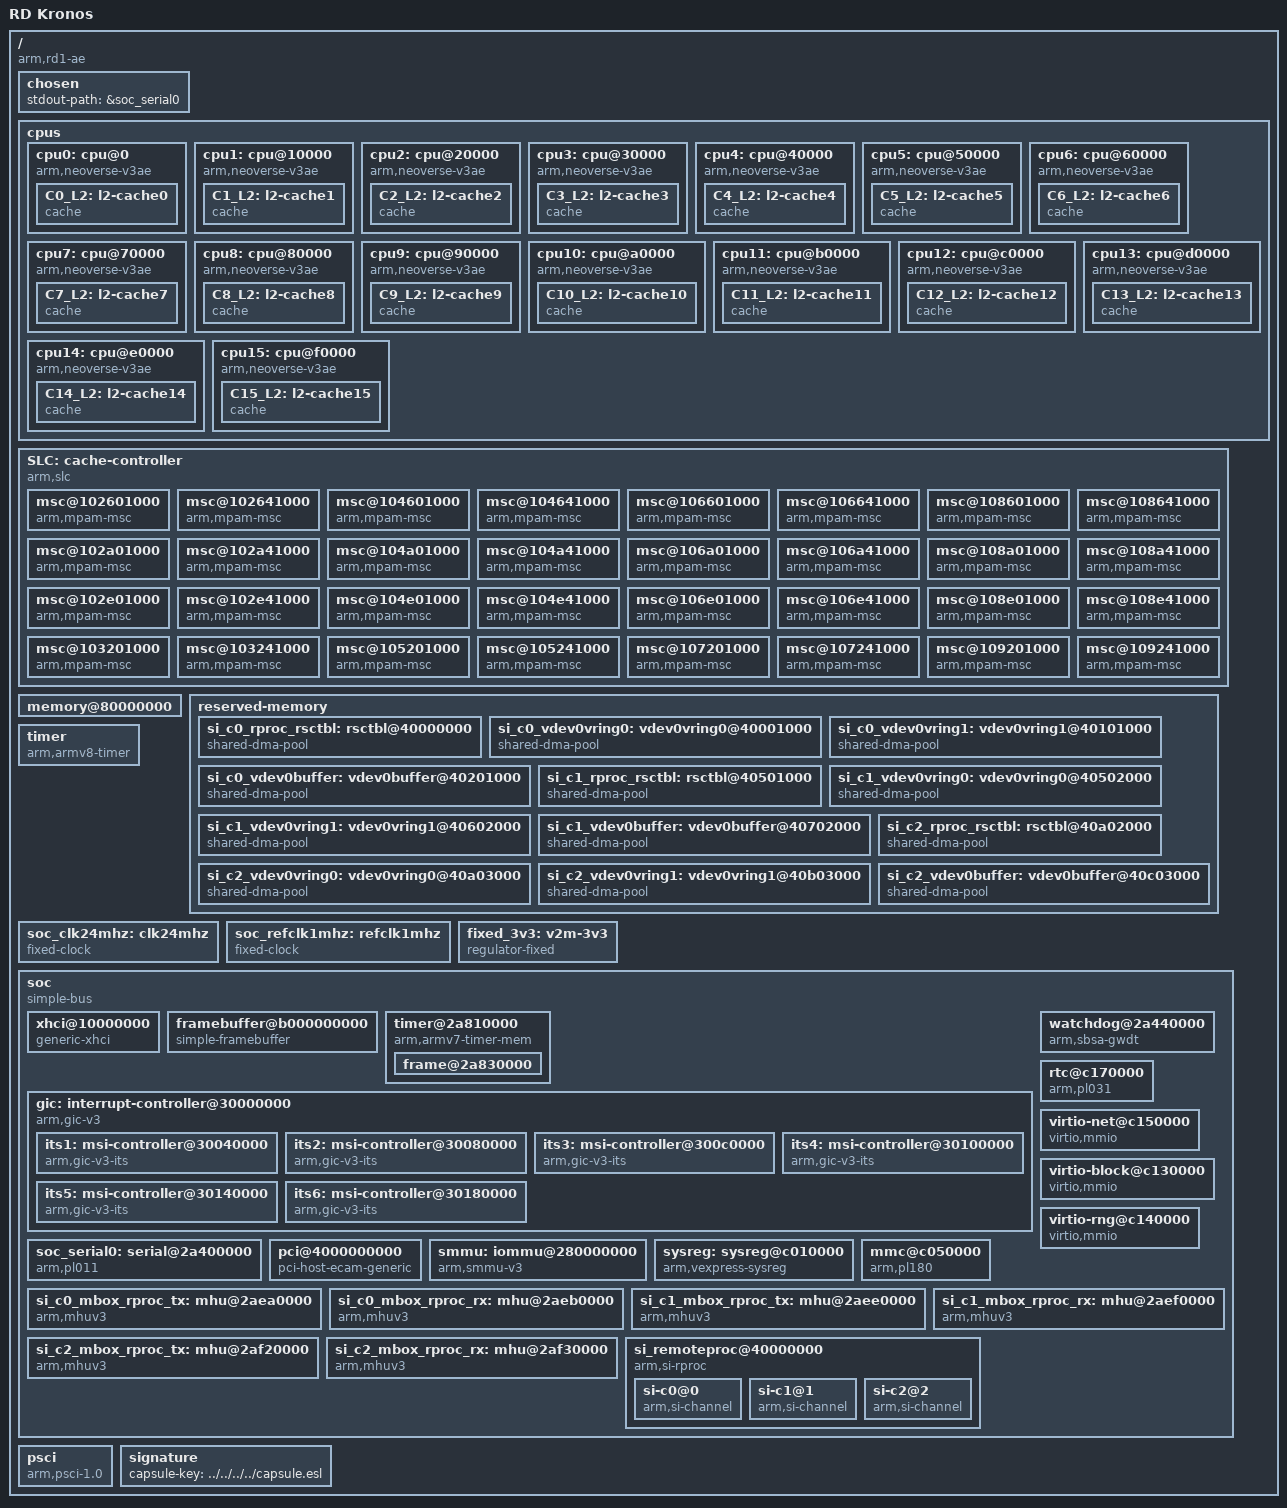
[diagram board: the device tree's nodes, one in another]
/*
 * SPDX-FileCopyrightText: <text>Copyright 2024 Arm Limited and/or its
 * affiliates <open-source-office@arm.com></text>
 *
 * SPDX-License-Identifier: MIT
 */

/dts-v1/;

#include <dt-bindings/interrupt-controller/arm-gic.h>

/ {
	model = "RD Kronos";
	compatible = "arm,rd1-ae";
	interrupt-parent = <&gic>;
	#address-cells = <2>;
	#size-cells = <2>;

	chosen {
		stdout-path = &soc_serial0;
	};

	cpus {
		#address-cells = <2>;
		#size-cells = <0>;

		cpu0: cpu@0 {
			device_type = "cpu";
			compatible = "arm,neoverse-v3ae";
			reg = <0x0 0x0>;
			enable-method = "psci";
			i-cache-size = <0x10000>;
			i-cache-line-size = <0x40>;
			i-cache-sets = <0x100>;
			d-cache-size = <0x10000>;
			d-cache-line-size = <0x40>;
			d-cache-sets = <0x100>;
			next-level-cache = <&C0_L2>;

			C0_L2: l2-cache0 {
				compatible = "cache";
				cache-unified;
				cache-level = <0x02>;
				cache-size = <0x100000>;
				cache-line-size = <0x40>;
				cache-sets = <0x800>;
				next-level-cache = <&SLC>;
			};
		};
		cpu1: cpu@10000 {
			device_type = "cpu";
			compatible = "arm,neoverse-v3ae";
			reg = <0x0 0x10000>;
			enable-method = "psci";
			i-cache-size = <0x10000>;
			i-cache-line-size = <0x40>;
			i-cache-sets = <0x100>;
			d-cache-size = <0x10000>;
			d-cache-line-size = <0x40>;
			d-cache-sets = <0x100>;
			next-level-cache = <&C1_L2>;

			C1_L2: l2-cache1 {
				compatible = "cache";
				cache-unified;
				cache-level = <0x02>;
				cache-size = <0x100000>;
				cache-line-size = <0x40>;
				cache-sets = <0x800>;
				next-level-cache = <&SLC>;
			};
		};
		cpu2: cpu@20000 {
			device_type = "cpu";
			compatible = "arm,neoverse-v3ae";
			reg = <0x0 0x20000>;
			enable-method = "psci";
			i-cache-size = <0x10000>;
			i-cache-line-size = <0x40>;
			i-cache-sets = <0x100>;
			d-cache-size = <0x10000>;
			d-cache-line-size = <0x40>;
			d-cache-sets = <0x100>;
			next-level-cache = <&C2_L2>;

			C2_L2: l2-cache2 {
				compatible = "cache";
				cache-unified;
				cache-level = <0x02>;
				cache-size = <0x100000>;
				cache-line-size = <0x40>;
				cache-sets = <0x800>;
				next-level-cache = <&SLC>;
			};
		};
		cpu3: cpu@30000 {
			device_type = "cpu";
			compatible = "arm,neoverse-v3ae";
			reg = <0x0 0x30000>;
			enable-method = "psci";
			i-cache-size = <0x10000>;
			i-cache-line-size = <0x40>;
			i-cache-sets = <0x100>;
			d-cache-size = <0x10000>;
			d-cache-line-size = <0x40>;
			d-cache-sets = <0x100>;
			next-level-cache = <&C3_L2>;

			C3_L2: l2-cache3 {
				compatible = "cache";
				cache-unified;
				cache-level = <0x02>;
				cache-size = <0x100000>;
				cache-line-size = <0x40>;
				cache-sets = <0x800>;
				next-level-cache = <&SLC>;
			};
		};
		cpu4: cpu@40000 {
			device_type = "cpu";
			compatible = "arm,neoverse-v3ae";
			reg = <0x0 0x40000>;
			enable-method = "psci";
			i-cache-size = <0x10000>;
			i-cache-line-size = <0x40>;
			i-cache-sets = <0x100>;
			d-cache-size = <0x10000>;
			d-cache-line-size = <0x40>;
			d-cache-sets = <0x100>;
			next-level-cache = <&C4_L2>;

			C4_L2: l2-cache4 {
				compatible = "cache";
				cache-unified;
				cache-level = <0x02>;
				cache-size = <0x100000>;
				cache-line-size = <0x40>;
				cache-sets = <0x800>;
				next-level-cache = <&SLC>;
			};
		};
		cpu5: cpu@50000 {
			device_type = "cpu";
			compatible = "arm,neoverse-v3ae";
			reg = <0x0 0x50000>;
			enable-method = "psci";
			i-cache-size = <0x10000>;
			i-cache-line-size = <0x40>;
			i-cache-sets = <0x100>;
			d-cache-size = <0x10000>;
			d-cache-line-size = <0x40>;
			d-cache-sets = <0x100>;
			next-level-cache = <&C5_L2>;

			C5_L2: l2-cache5 {
				compatible = "cache";
				cache-unified;
				cache-level = <0x02>;
				cache-size = <0x100000>;
				cache-line-size = <0x40>;
				cache-sets = <0x800>;
				next-level-cache = <&SLC>;
			};
		};
		cpu6: cpu@60000 {
			device_type = "cpu";
			compatible = "arm,neoverse-v3ae";
			reg = <0x0 0x60000>;
			enable-method = "psci";
			i-cache-size = <0x10000>;
			i-cache-line-size = <0x40>;
			i-cache-sets = <0x100>;
			d-cache-size = <0x10000>;
			d-cache-line-size = <0x40>;
			d-cache-sets = <0x100>;
			next-level-cache = <&C6_L2>;

			C6_L2: l2-cache6 {
				compatible = "cache";
				cache-unified;
				cache-level = <0x02>;
				cache-size = <0x100000>;
				cache-line-size = <0x40>;
				cache-sets = <0x800>;
				next-level-cache = <&SLC>;
			};
		};
		cpu7: cpu@70000 {
			device_type = "cpu";
			compatible = "arm,neoverse-v3ae";
			reg = <0x0 0x70000>;
			enable-method = "psci";
			i-cache-size = <0x10000>;
			i-cache-line-size = <0x40>;
			i-cache-sets = <0x100>;
			d-cache-size = <0x10000>;
			d-cache-line-size = <0x40>;
			d-cache-sets = <0x100>;
			next-level-cache = <&C7_L2>;

			C7_L2: l2-cache7 {
				compatible = "cache";
				cache-unified;
				cache-level = <0x02>;
				cache-size = <0x100000>;
				cache-line-size = <0x40>;
				cache-sets = <0x800>;
				next-level-cache = <&SLC>;
			};
		};
		cpu8: cpu@80000 {
			device_type = "cpu";
			compatible = "arm,neoverse-v3ae";
			reg = <0x0 0x80000>;
			enable-method = "psci";
			i-cache-size = <0x10000>;
			i-cache-line-size = <0x40>;
			i-cache-sets = <0x100>;
			d-cache-size = <0x10000>;
			d-cache-line-size = <0x40>;
			d-cache-sets = <0x100>;
			next-level-cache = <&C8_L2>;

			C8_L2: l2-cache8 {
				compatible = "cache";
				cache-unified;
				cache-level = <0x02>;
				cache-size = <0x100000>;
				cache-line-size = <0x40>;
				cache-sets = <0x800>;
				next-level-cache = <&SLC>;
			};
		};
		cpu9: cpu@90000 {
			device_type = "cpu";
			compatible = "arm,neoverse-v3ae";
			reg = <0x0 0x90000>;
			enable-method = "psci";
			i-cache-size = <0x10000>;
			i-cache-line-size = <0x40>;
			i-cache-sets = <0x100>;
			d-cache-size = <0x10000>;
			d-cache-line-size = <0x40>;
			d-cache-sets = <0x100>;
			next-level-cache = <&C9_L2>;

			C9_L2: l2-cache9 {
				compatible = "cache";
				cache-unified;
				cache-level = <0x02>;
				cache-size = <0x100000>;
				cache-line-size = <0x40>;
				cache-sets = <0x800>;
				next-level-cache = <&SLC>;
			};
		};
		cpu10: cpu@a0000 {
			device_type = "cpu";
			compatible = "arm,neoverse-v3ae";
			reg = <0x0 0xa0000>;
			enable-method = "psci";
			i-cache-size = <0x10000>;
			i-cache-line-size = <0x40>;
			i-cache-sets = <0x100>;
			d-cache-size = <0x10000>;
			d-cache-line-size = <0x40>;
			d-cache-sets = <0x100>;
			next-level-cache = <&C10_L2>;

			C10_L2: l2-cache10 {
				compatible = "cache";
				cache-unified;
				cache-level = <0x02>;
				cache-size = <0x100000>;
				cache-line-size = <0x40>;
				cache-sets = <0x800>;
				next-level-cache = <&SLC>;
			};
		};
		cpu11: cpu@b0000 {
			device_type = "cpu";
			compatible = "arm,neoverse-v3ae";
			reg = <0x0 0xb0000>;
			enable-method = "psci";
			i-cache-size = <0x10000>;
			i-cache-line-size = <0x40>;
			i-cache-sets = <0x100>;
			d-cache-size = <0x10000>;
			d-cache-line-size = <0x40>;
			d-cache-sets = <0x100>;
			next-level-cache = <&C11_L2>;

			C11_L2: l2-cache11 {
				compatible = "cache";
				cache-unified;
				cache-level = <0x02>;
				cache-size = <0x100000>;
				cache-line-size = <0x40>;
				cache-sets = <0x800>;
				next-level-cache = <&SLC>;
			};
		};
		cpu12: cpu@c0000 {
			device_type = "cpu";
			compatible = "arm,neoverse-v3ae";
			reg = <0x0 0xc0000>;
			enable-method = "psci";
			i-cache-size = <0x10000>;
			i-cache-line-size = <0x40>;
			i-cache-sets = <0x100>;
			d-cache-size = <0x10000>;
			d-cache-line-size = <0x40>;
			d-cache-sets = <0x100>;
			next-level-cache = <&C12_L2>;

			C12_L2: l2-cache12 {
				compatible = "cache";
				cache-unified;
				cache-level = <0x02>;
				cache-size = <0x100000>;
				cache-line-size = <0x40>;
				cache-sets = <0x800>;
				next-level-cache = <&SLC>;
			};
		};
		cpu13: cpu@d0000 {
			device_type = "cpu";
			compatible = "arm,neoverse-v3ae";
			reg = <0x0 0xd0000>;
			enable-method = "psci";
			i-cache-size = <0x10000>;
			i-cache-line-size = <0x40>;
			i-cache-sets = <0x100>;
			d-cache-size = <0x10000>;
			d-cache-line-size = <0x40>;
			d-cache-sets = <0x100>;
			next-level-cache = <&C13_L2>;

			C13_L2: l2-cache13 {
				compatible = "cache";
				cache-unified;
				cache-level = <0x02>;
				cache-size = <0x100000>;
				cache-line-size = <0x40>;
				cache-sets = <0x800>;
				next-level-cache = <&SLC>;
			};
		};
		cpu14: cpu@e0000 {
			device_type = "cpu";
			compatible = "arm,neoverse-v3ae";
			reg = <0x0 0xe0000>;
			enable-method = "psci";
			i-cache-size = <0x10000>;
			i-cache-line-size = <0x40>;
			i-cache-sets = <0x100>;
			d-cache-size = <0x10000>;
			d-cache-line-size = <0x40>;
			d-cache-sets = <0x100>;
			next-level-cache = <&C14_L2>;

			C14_L2: l2-cache14 {
				compatible = "cache";
				cache-unified;
				cache-level = <0x02>;
				cache-size = <0x100000>;
				cache-line-size = <0x40>;
				cache-sets = <0x800>;
				next-level-cache = <&SLC>;
			};
		};
		cpu15: cpu@f0000 {
			device_type = "cpu";
			compatible = "arm,neoverse-v3ae";
			reg = <0x0 0xf0000>;
			enable-method = "psci";
			i-cache-size = <0x10000>;
			i-cache-line-size = <0x40>;
			i-cache-sets = <0x100>;
			d-cache-size = <0x10000>;
			d-cache-line-size = <0x40>;
			d-cache-sets = <0x100>;
			next-level-cache = <&C15_L2>;

			C15_L2: l2-cache15 {
				compatible = "cache";
				cache-unified;
				cache-level = <0x02>;
				cache-size = <0x100000>;
				cache-line-size = <0x40>;
				cache-sets = <0x800>;
				next-level-cache = <&SLC>;
			};
		};
	};

	SLC: cache-controller {
		compatible = "arm,slc", "cache";
		cache-level = <0x03>;
		cache-unified;
		cache-line-size = <0x40>;
		cache-sets = <0x8000>;
		cache-size = <0x2000000>;
		#address-cells = <0x02>;
		#size-cells = <0x01>;

		msc@102601000 {
			compatible = "arm,mpam-msc";
			reg = <0x01 0x2601000 0x3000>;
			arm,not-ready-us = <0x10>;
		};

		msc@102641000 {
			compatible = "arm,mpam-msc";
			reg = <0x01 0x2641000 0x3000>;
			arm,not-ready-us = <0x10>;
		};

		msc@104601000 {
			compatible = "arm,mpam-msc";
			reg = <0x01 0x4601000 0x3000>;
			arm,not-ready-us = <0x10>;
		};

		msc@104641000 {
			compatible = "arm,mpam-msc";
			reg = <0x01 0x4641000 0x3000>;
			arm,not-ready-us = <0x10>;
		};

		msc@106601000 {
			compatible = "arm,mpam-msc";
			reg = <0x01 0x6601000 0x3000>;
			arm,not-ready-us = <0x10>;
		};

		msc@106641000 {
			compatible = "arm,mpam-msc";
			reg = <0x01 0x6641000 0x3000>;
			arm,not-ready-us = <0x10>;
		};

		msc@108601000 {
			compatible = "arm,mpam-msc";
			reg = <0x01 0x8601000 0x3000>;
			arm,not-ready-us = <0x10>;
		};

		msc@108641000 {
			compatible = "arm,mpam-msc";
			reg = <0x01 0x8641000 0x3000>;
			arm,not-ready-us = <0x10>;
		};

		msc@102a01000 {
			compatible = "arm,mpam-msc";
			reg = <0x01 0x2a01000 0x3000>;
			arm,not-ready-us = <0x10>;
		};

		msc@102a41000 {
			compatible = "arm,mpam-msc";
			reg = <0x01 0x2a41000 0x3000>;
			arm,not-ready-us = <0x10>;
		};

		msc@104a01000 {
			compatible = "arm,mpam-msc";
			reg = <0x01 0x4a01000 0x3000>;
			arm,not-ready-us = <0x10>;
		};

		msc@104a41000 {
			compatible = "arm,mpam-msc";
			reg = <0x01 0x4a41000 0x3000>;
			arm,not-ready-us = <0x10>;
		};

		msc@106a01000 {
			compatible = "arm,mpam-msc";
			reg = <0x01 0x6a01000 0x3000>;
			arm,not-ready-us = <0x10>;
		};

		msc@106a41000 {
			compatible = "arm,mpam-msc";
			reg = <0x01 0x6a41000 0x3000>;
			arm,not-ready-us = <0x10>;
		};

		msc@108a01000 {
			compatible = "arm,mpam-msc";
			reg = <0x01 0x8a01000 0x3000>;
			arm,not-ready-us = <0x10>;
		};

		msc@108a41000 {
			compatible = "arm,mpam-msc";
			reg = <0x01 0x8a41000 0x3000>;
			arm,not-ready-us = <0x10>;
		};

		msc@102e01000 {
			compatible = "arm,mpam-msc";
			reg = <0x01 0x2e01000 0x3000>;
			arm,not-ready-us = <0x10>;
		};

		msc@102e41000 {
			compatible = "arm,mpam-msc";
			reg = <0x01 0x2e41000 0x3000>;
			arm,not-ready-us = <0x10>;
		};

		msc@104e01000 {
			compatible = "arm,mpam-msc";
			reg = <0x01 0x4e01000 0x3000>;
			arm,not-ready-us = <0x10>;
		};

		msc@104e41000 {
			compatible = "arm,mpam-msc";
			reg = <0x01 0x4e41000 0x3000>;
			arm,not-ready-us = <0x10>;
		};

		msc@106e01000 {
			compatible = "arm,mpam-msc";
			reg = <0x01 0x6e01000 0x3000>;
			arm,not-ready-us = <0x10>;
		};

		msc@106e41000 {
			compatible = "arm,mpam-msc";
			reg = <0x01 0x6e41000 0x3000>;
			arm,not-ready-us = <0x10>;
		};

		msc@108e01000 {
			compatible = "arm,mpam-msc";
			reg = <0x01 0x8e01000 0x3000>;
			arm,not-ready-us = <0x10>;
		};

		msc@108e41000 {
			compatible = "arm,mpam-msc";
			reg = <0x01 0x8e41000 0x3000>;
			arm,not-ready-us = <0x10>;
		};

		msc@103201000 {
			compatible = "arm,mpam-msc";
			reg = <0x01 0x3201000 0x3000>;
			arm,not-ready-us = <0x10>;
		};

		msc@103241000 {
			compatible = "arm,mpam-msc";
			reg = <0x01 0x3241000 0x3000>;
			arm,not-ready-us = <0x10>;
		};

		msc@105201000 {
			compatible = "arm,mpam-msc";
			reg = <0x01 0x5201000 0x3000>;
			arm,not-ready-us = <0x10>;
		};

		msc@105241000 {
			compatible = "arm,mpam-msc";
			reg = <0x01 0x5241000 0x3000>;
			arm,not-ready-us = <0x10>;
		};

		msc@107201000 {
			compatible = "arm,mpam-msc";
			reg = <0x01 0x7201000 0x3000>;
			arm,not-ready-us = <0x10>;
		};

		msc@107241000 {
			compatible = "arm,mpam-msc";
			reg = <0x01 0x7241000 0x3000>;
			arm,not-ready-us = <0x10>;
		};

		msc@109201000 {
			compatible = "arm,mpam-msc";
			reg = <0x01 0x9201000 0x3000>;
			arm,not-ready-us = <0x10>;
		};

		msc@109241000 {
			compatible = "arm,mpam-msc";
			reg = <0x01 0x9241000 0x3000>;
			arm,not-ready-us = <0x10>;
		};
	};

	memory@80000000 {
		device_type = "memory";
		/*
		 * 0x7fc0 0000 - 0x7fff ffff : BL32
		 * 0x7fbf 0000 - 0x7fbf ffff : FFA_SHARED_MM_BUF
		 */
		reg = <0x00000000 0x80000000 0 0x7fbf0000>,
			  <0x00000080 0x80000000 0x00000003 0x80000000>;
	};

	reserved-memory {
		#address-cells = <2>;
		#size-cells = <2>;
		ranges;

		si_c0_rproc_rsctbl: rsctbl@40000000 {
			compatible = "shared-dma-pool";
			reg = <0x0 0x40000000 0x0 0x1000>;
			no-map;
		};

		si_c0_vdev0vring0: vdev0vring0@40001000 {
			compatible = "shared-dma-pool";
			reg = <0x0 0x40001000 0x0 0x100000>;
			no-map;
		};

		si_c0_vdev0vring1: vdev0vring1@40101000 {
			compatible = "shared-dma-pool";
			reg = <0x0 0x40101000 0x0 0x100000>;
			no-map;
		};

		si_c0_vdev0buffer: vdev0buffer@40201000 {
			compatible = "shared-dma-pool";
			reg = <0x0 0x40201000 0x0 0x300000>;
			no-map;
		};

		si_c1_rproc_rsctbl: rsctbl@40501000 {
			compatible = "shared-dma-pool";
			reg = <0x0 0x40501000 0x0 0x1000>;
			no-map;
		};

		si_c1_vdev0vring0: vdev0vring0@40502000 {
			compatible = "shared-dma-pool";
			reg = <0x0 0x40502000 0x0 0x100000>;
			no-map;
		};

		si_c1_vdev0vring1: vdev0vring1@40602000 {
			compatible = "shared-dma-pool";
			reg = <0x0 0x40602000 0x0 0x100000>;
			no-map;
		};

		si_c1_vdev0buffer: vdev0buffer@40702000 {
			compatible = "shared-dma-pool";
			reg = <0x0 0x40702000 0x0 0x300000>;
			no-map;
		};

		si_c2_rproc_rsctbl: rsctbl@40a02000 {
			compatible = "shared-dma-pool";
			reg = <0x0 0x40a02000 0x0 0x1000>;
			no-map;
		};

		si_c2_vdev0vring0: vdev0vring0@40a03000 {
			compatible = "shared-dma-pool";
			reg = <0x0 0x40a03000 0x0 0x100000>;
			no-map;
		};

		si_c2_vdev0vring1: vdev0vring1@40b03000 {
			compatible = "shared-dma-pool";
			reg = <0x0 0x40b03000 0x0 0x100000>;
			no-map;
		};

		si_c2_vdev0buffer: vdev0buffer@40c03000 {
			compatible = "shared-dma-pool";
			reg = <0x0 0x40c03000 0x0 0x300000>;
			no-map;
		};
	};

	timer {
		compatible = "arm,armv8-timer";
		interrupts = <GIC_PPI 13 IRQ_TYPE_LEVEL_LOW>,
			<GIC_PPI 14 IRQ_TYPE_LEVEL_LOW>,
			<GIC_PPI 11 IRQ_TYPE_LEVEL_LOW>,
			<GIC_PPI 10 IRQ_TYPE_LEVEL_LOW>;
	};

	soc_clk24mhz: clk24mhz {
		compatible = "fixed-clock";
		#clock-cells = <0>;
		clock-frequency = <24000000>;
		clock-output-names = "refclk24mhz";
	};

	soc_refclk1mhz: refclk1mhz {
		compatible = "fixed-clock";
		#clock-cells = <0>;
		clock-frequency = <1000000>;
		clock-output-names = "refclk1mhz";
	};

	fixed_3v3: v2m-3v3 {
		compatible = "regulator-fixed";
		regulator-name = "3v3";
		regulator-min-microvolt = <3300000>;
		regulator-max-microvolt = <3300000>;
		regulator-always-on;
	};
	
	soc {
		compatible = "simple-bus";
		#address-cells = <2>;
		#size-cells = <2>;
		ranges;

        xhci@10000000 {
            compatible = "generic-xhci";
            reg = <0 0x10000000 0 0x10000>;
            interrupts = <0x00 0x33 0x04>;
        };

        framebuffer@b000000000 {
            compatible = "simple-framebuffer";
            reg = <0xb0 0x0 0x0 (1920*1080*4)>;
            width = <1920>;
            height = <1080>;
            stride = <(1920*4)>;
            format = "a8b8g8r8";
        };

		timer@2a810000 {
			compatible = "arm,armv7-timer-mem";
			reg = <0x0 0x2a810000 0 0x10000>;
			#address-cells = <2>;
			#size-cells = <1>;
			clock-frequency = <250000000>;
			ranges = <0x0 0x2a810000 0x0 0x2a810000 0x30000>;

			frame@2a830000 {
				frame-number = <0>;
				interrupts = <GIC_SPI 77 IRQ_TYPE_LEVEL_HIGH>;
				reg = <0x0 0x2a830000 0x10000>;
			};
		};

		gic: interrupt-controller@30000000 {
			compatible = "arm,gic-v3";
			reg = <0x0 0x30000000 0 0x10000>,	// GICD
				  <0x0 0x301c0000 0 0x400000>;	// GICR
			#interrupt-cells = <3>;
			#address-cells = <2>;
			#size-cells = <2>;
			ranges;
			interrupt-controller;
			interrupts = <GIC_PPI 9 IRQ_TYPE_LEVEL_HIGH>;

			its1: msi-controller@30040000 {
				compatible = "arm,gic-v3-its";
				reg = <0x0 0x30040000 0x0 0x40000>;
				msi-controller;
				#msi-cells = <1>;
			};
			its2: msi-controller@30080000 {
				compatible = "arm,gic-v3-its";
				reg = <0x0 0x30080000 0x0 0x40000>;
				msi-controller;
				#msi-cells = <1>;
			};
			its3: msi-controller@300c0000 {
				compatible = "arm,gic-v3-its";
				reg = <0x0 0x300c0000 0x0 0x40000>;
				msi-controller;
				#msi-cells = <1>;
			};
			its4: msi-controller@30100000 {
				compatible = "arm,gic-v3-its";
				reg = <0x0 0x30100000 0x0 0x40000>;
				msi-controller;
				#msi-cells = <1>;
			};
			its5: msi-controller@30140000 {
				compatible = "arm,gic-v3-its";
				reg = <0x0 0x30140000 0x0 0x40000>;
				msi-controller;
				#msi-cells = <1>;
			};
			its6: msi-controller@30180000 {
				compatible = "arm,gic-v3-its";
				reg = <0x0 0x30180000 0x0 0x40000>;
				msi-controller;
				#msi-cells = <1>;
			};
		};

		soc_serial0: serial@2a400000 {
			compatible = "arm,pl011", "arm,primecell";
			reg = <0x0 0x2a400000 0x0 0x10000>;
			interrupts = <GIC_SPI 80 IRQ_TYPE_LEVEL_HIGH>;
			clocks = <&soc_clk24mhz>, <&soc_clk24mhz>;
			clock-names = "uartclk", "apb_pclk";
		};

		watchdog@2a440000 {
			compatible = "arm,sbsa-gwdt";
			reg = <0x0 0x2a440000 0 0x1000>,
				  <0x0 0x2a450000 0 0x1000>;
			interrupts = <GIC_SPI 78 IRQ_TYPE_LEVEL_HIGH>;
		};

		rtc@c170000 {
			compatible = "arm,pl031", "arm,primecell";
			reg = <0x0 0x0c170000 0x0 0x10000>;
			interrupts = <GIC_SPI 132 IRQ_TYPE_LEVEL_HIGH>;
			clocks = <&soc_clk24mhz>;
			clock-names = "apb_pclk";
		};

		virtio-net@c150000 {
			compatible = "virtio,mmio";
			reg = <0x0 0xc150000 0x0 0x200>;
			interrupts = <GIC_SPI 154 IRQ_TYPE_LEVEL_HIGH>;
		};

		virtio-block@c130000 {
			compatible = "virtio,mmio";
			reg = <0x0 0xc130000 0x0 0x200>;
			interrupts = <GIC_SPI 152 IRQ_TYPE_LEVEL_HIGH>;
		};

		virtio-rng@c140000 {
			compatible = "virtio,mmio";
			reg = <0x0 0xc140000 0x0 0x200>;
			interrupts = <GIC_SPI 156 IRQ_TYPE_LEVEL_HIGH>;
		};

		pci@4000000000 {
			#address-cells = <0x03>;
			#size-cells = <0x02>;
			compatible = "pci-host-ecam-generic";
			device_type = "pci";
			bus-range = <0x0 0x11>;
			reg = <0x40 0x0 0x0 0x04000000>;
			ranges = <0x43000000 0x40 0x40000000 0x40 0x40000000 0x10 0x00000000
				  0x02000000 0x0 0x60000000 0x0 0x60000000 0x0 0x08000000
				  0x01000000 0x0 0x0 0x0 0x77800000 0x0 0x800000>;
			msi-map = <0x0 &its1 0x40000 0x10000>;
			iommu-map = <0x0 &smmu 0x40000 0x10000>;
			dma-coherent;
		};

		smmu: iommu@280000000 {
			compatible = "arm,smmu-v3";
			reg = <0x2 0x80000000 0x0 0x100000>;
			dma-coherent;
			#iommu-cells = <1>;
			interrupts = <GIC_SPI 210 IRQ_TYPE_EDGE_RISING>,
				     <GIC_SPI 211 IRQ_TYPE_EDGE_RISING>,
				     <GIC_SPI 212 IRQ_TYPE_EDGE_RISING>,
				     <GIC_SPI 213 IRQ_TYPE_EDGE_RISING>;
			interrupt-names = "eventq", "priq", "cmdq-sync", "gerror";
			msi-parent = <&its1 0x10000>;
		};

		sysreg: sysreg@c010000 {
			compatible = "arm,vexpress-sysreg";
			reg = <0x0 0xc010000 0x0 0x1000>;
			gpio-controller;
			#gpio-cells = <2>;
		};

		mmc@c050000 {
			compatible = "arm,pl180", "arm,primecell";
			reg = <0x0 0xc050000 0x0 0x1000>;
			interrupts = <GIC_SPI 139 IRQ_TYPE_LEVEL_HIGH>,
				     <GIC_SPI 140 IRQ_TYPE_LEVEL_HIGH>;
			cd-gpios = <&sysreg 0 0>;
			wp-gpios = <&sysreg 1 0>;
			bus-width = <8>;
			max-frequency = <12000000>;
			vmmc-supply = <&fixed_3v3>;
			clocks = <&soc_clk24mhz>, <&soc_clk24mhz>;
			clock-names = "mclk", "apb_pclk";
		};

		si_c0_mbox_rproc_tx: mhu@2aea0000 {
			compatible = "arm,mhuv3";
			reg = <0x0 0x2aea0000 0x0 0x10000>;
			clocks = <&soc_clk24mhz>;
			#mbox-cells = <3>;
			interrupt-names = "combined";
			interrupts = <GIC_SPI 93 IRQ_TYPE_LEVEL_HIGH>;
		};

		si_c0_mbox_rproc_rx: mhu@2aeb0000 {
			compatible = "arm,mhuv3";
			reg = <0x0 0x2aeb0000 0x0 0x10000>;
			clocks = <&soc_clk24mhz>;
			#mbox-cells = <3>;
			interrupt-names = "combined";
			interrupts = <GIC_SPI 92 IRQ_TYPE_LEVEL_HIGH>;
		};

		si_c1_mbox_rproc_tx: mhu@2aee0000 {
			compatible = "arm,mhuv3";
			reg = <0x0 0x2aee0000 0x0 0x10000>;
			clocks = <&soc_clk24mhz>;
			#mbox-cells = <3>;
			interrupt-names = "combined";
			interrupts = <GIC_SPI 89 IRQ_TYPE_LEVEL_HIGH>;
		};

		si_c1_mbox_rproc_rx: mhu@2aef0000 {
			compatible = "arm,mhuv3";
			reg = <0x0 0x2aef0000 0x0 0x10000>;
			clocks = <&soc_clk24mhz>;
			#mbox-cells = <3>;
			interrupt-names = "combined";
			interrupts = <GIC_SPI 88 IRQ_TYPE_LEVEL_HIGH>;
		};

		si_c2_mbox_rproc_tx: mhu@2af20000 {
			compatible = "arm,mhuv3";
			reg = <0x0 0x2af20000 0x0 0x10000>;
			clocks = <&soc_clk24mhz>;
			#mbox-cells = <3>;
			interrupt-names = "combined";
			interrupts = <GIC_SPI 85 IRQ_TYPE_LEVEL_HIGH>;
		};

		si_c2_mbox_rproc_rx: mhu@2af30000 {
			compatible = "arm,mhuv3";
			reg = <0x0 0x2af30000 0x0 0x10000>;
			clocks = <&soc_clk24mhz>;
			#mbox-cells = <3>;
			interrupt-names = "combined";
			interrupts = <GIC_SPI 84 IRQ_TYPE_LEVEL_HIGH>;
		};

		si_remoteproc@40000000 {
			compatible = "arm,si-rproc";
			ranges = <0x2 0x00000000 0x0 0x40000000 0x0 0x01000000>;
			#address-cells = <2>;
			#size-cells = <2>;
			si-c0@0 {
				compatible = "arm,si-channel";
				#address-cells = <1>;
				#size-cells = <1>;
				ranges = <0x2 0x00000000 0x0 0x40000000>;
				memory-region = <&si_c0_rproc_rsctbl>,
						<&si_c0_vdev0vring0>,
						<&si_c0_vdev0vring1>,
						<&si_c0_vdev0buffer>;
				mboxes = <&si_c0_mbox_rproc_rx 0 0 0>,	// RX - DBE, Channel Window 0, Doorbell 0
					 <&si_c0_mbox_rproc_rx 0 0 1>,	// RX - DBE, Channel Window 0, Doorbell 1
					 <&si_c0_mbox_rproc_tx 0 0 0>,	// TX - DBE, Channel Window 0, Doorbell 0
					 <&si_c0_mbox_rproc_tx 0 0 1>,	// TX - DBE, Channel Window 0, Doorbell 1
					 <&si_c0_mbox_rproc_tx 0 0 2>,	// TX - DBE, Channel Window 0, Doorbell 2
					 <&si_c0_mbox_rproc_tx 0 0 3>,	// TX - DBE, Channel Window 0, Doorbell 3
					 <&si_c0_mbox_rproc_rx 0 0 2>;	// RX - DBE, Channel Window 0, Doorbell 2
				mbox-names = "vq0_rx", "vq1_rx", "vq0_tx",
					     "vq1_tx", "detach", "attach",
					     "ack";
			};

			si-c1@1 {
				compatible = "arm,si-channel";
				#address-cells = <1>;
				#size-cells = <1>;
				ranges = <0x2 0x00000000 0x0 0x40000000>;
				memory-region = <&si_c1_rproc_rsctbl>,
						<&si_c1_vdev0vring0>,
						<&si_c1_vdev0vring1>,
						<&si_c1_vdev0buffer>;
				mboxes = <&si_c1_mbox_rproc_rx 0 0 0>,	// RX - DBE, Channel Window 0, Doorbell 0
					 <&si_c1_mbox_rproc_rx 0 0 1>,	// RX - DBE, Channel Window 0, Doorbell 1
					 <&si_c1_mbox_rproc_tx 0 0 0>,	// TX - DBE, Channel Window 0, Doorbell 0
					 <&si_c1_mbox_rproc_tx 0 0 1>,	// TX - DBE, Channel Window 0, Doorbell 1
					 <&si_c1_mbox_rproc_tx 0 0 2>,	// TX - DBE, Channel Window 0, Doorbell 2
					 <&si_c1_mbox_rproc_tx 0 0 3>,	// TX - DBE, Channel Window 0, Doorbell 3
					 <&si_c1_mbox_rproc_rx 0 0 2>;	// RX - DBE, Channel Window 0, Doorbell 2
				mbox-names = "vq0_rx", "vq1_rx", "vq0_tx",
					     "vq1_tx", "detach", "attach",
					     "ack";
			};

			si-c2@2 {
				compatible = "arm,si-channel";
				#address-cells = <1>;
				#size-cells = <1>;
				ranges = <0x2 0x00000000 0x0 0x40000000>;
				memory-region = <&si_c2_rproc_rsctbl>,
						<&si_c2_vdev0vring0>,
						<&si_c2_vdev0vring1>,
						<&si_c2_vdev0buffer>;
				mboxes = <&si_c2_mbox_rproc_rx 0 0 0>,	// RX - DBE, Channel Window 0, Doorbell 0
					 <&si_c2_mbox_rproc_rx 0 0 1>,	// RX - DBE, Channel Window 0, Doorbell 1
					 <&si_c2_mbox_rproc_tx 0 0 0>,	// TX - DBE, Channel Window 0, Doorbell 0
					 <&si_c2_mbox_rproc_tx 0 0 1>,	// TX - DBE, Channel Window 0, Doorbell 1
					 <&si_c2_mbox_rproc_tx 0 0 2>,	// TX - DBE, Channel Window 0, Doorbell 2
					 <&si_c2_mbox_rproc_tx 0 0 3>,	// TX - DBE, Channel Window 0, Doorbell 3
					 <&si_c2_mbox_rproc_rx 0 0 2>;	// RX - DBE, Channel Window 0, Doorbell 2
				mbox-names = "vq0_rx", "vq1_rx", "vq0_tx",
					     "vq1_tx", "detach", "attach",
					     "ack";
			};

		};
	};

	psci {
		compatible = "arm,psci-1.0", "arm,psci-0.2", "arm,psci";
		method = "smc";
		cpu_suspend = <0xc4000001>;
		cpu_off = <0x84000002>;
		cpu_on = <0xc4000003>;
	};

	signature {
		capsule-key = /incbin/("../../../../capsule.esl");
	};
};
